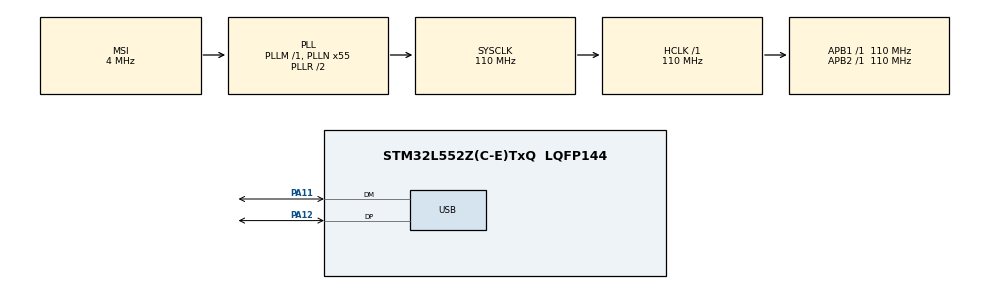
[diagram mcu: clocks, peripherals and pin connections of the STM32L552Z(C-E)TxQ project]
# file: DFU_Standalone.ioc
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Mcu.Family=STM32L5
Mcu.Name=STM32L552Z(C-E)TxQ
Mcu.Package=LQFP144
NVIC.PriorityGroup=NVIC_PRIORITYGROUP_3
NVIC.USB_FS_IRQn=true\:0\:0\:true\:false\:true\:false\:true\:true
PA11.GPIO_Speed=GPIO_SPEED_FREQ_VERY_HIGH
PA11.Mode=Device
PA11.Signal=USB_DM
PA12.GPIO_Speed=GPIO_SPEED_FREQ_VERY_HIGH
PA12.Mode=Device
PA12.Signal=USB_DP
ProjectManager.HeapSize=0x1000
ProjectManager.StackSize=0x1000
ProjectManager.TargetToolchain=EWARM V8.32
RCC.ADCCLockSelection=RCC_ADCCLKSOURCE_SYSCLK
RCC.ADCFreq_Value=110000000
RCC.AHBFreq_Value=110000000
RCC.APB1Freq_Value=110000000
RCC.APB1TimFreq_Value=110000000
RCC.APB2Freq_Value=110000000
RCC.APB2TimFreq_Value=110000000
RCC.CK48CLockSelection=RCC_USBCLKSOURCE_HSI48
RCC.CortexFreq_Value=110000000
RCC.DATA_CACHE_ENABLE=0
RCC.HCLKFreq_Value=110000000
RCC.HSE_VALUE=8000000
RCC.HSI48_VALUE=48000000
RCC.HSI_VALUE=16000000
RCC.INSTRUCTION_CACHE_ENABLE=0
RCC.LSE_VALUE=32768
RCC.MSI_VALUE=4000000
RCC.PLLN=55
RCC.SYSCLKFreq_VALUE=110000000
RCC.SYSCLKSource=RCC_SYSCLKSOURCE_PLLCLK
RCC.USBFreq_Value=48000000
RCC.VCOOutputFreq_Value=220000000
USB.DeviceSpeed=PCD_SPEED_FULL
USB.Sof_enable=DISABLE
USB.battery_charging_enable=DISABLE
USB.low_power_enable=DISABLE
USB.lpm_enable=DISABLE
USB.phy_itface=PCD_PHY_EMBEDDED
USB_DEVICE.CLASS_NAME_FS=DFU
USB_DEVICE.CONFIGURATION_STRING_DFU_FS=DFU Config
USB_DEVICE.INTERFACE_STRING_DFU_FS=DFU Interface
USB_DEVICE.LANGID_STRING=1033
USB_DEVICE.MANUFACTURER_STRING=STMicroelectronics
USB_DEVICE.PID_DFU_FS=0xdf11
USB_DEVICE.PRODUCT_STRING_DFU_FS=DFU in FS Mode
USB_DEVICE.USBD_DEBUG_LEVEL=0
USB_DEVICE.USBD_DFU_APP_DEFAULT_ADD=0x0800C000
USB_DEVICE.USBD_DFU_MAX_ITF_NUM=1
USB_DEVICE.USBD_DFU_MEDIA=@Internal Flash   /0x08000000/9*02Ka,247*02Kg
USB_DEVICE.USBD_DFU_XFER_SIZE=1024
USB_DEVICE.USBD_LPM_ENABLED=0
USB_DEVICE.USBD_MAX_NUM_CONFIGURATION=1
USB_DEVICE.USBD_MAX_NUM_INTERFACES=1
USB_DEVICE.USBD_MAX_STR_DESC_SIZ=48
USB_DEVICE.USBD_SELF_POWERED=1
USB_DEVICE.USBD_SUPPORT_USER_STRING_DESC=1
USB_DEVICE.VID=0x483
USB_DEVICE.VirtualMode=Dfu
USB_DEVICE.VirtualModeFS=Dfu_FS
VP_PWR_VS_DBSignals.Mode=DisableDeadBatterySignals
VP_PWR_VS_SECSignals.Mode=Security/Privilege
VP_RCC_USB.Mode=CRS SYNC Source USB
VP_USB_DEVICE_VS_USB_DEVICE_DFU_FS.Mode=DFU_FS
board=STM32L552E_EVAL

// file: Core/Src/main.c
/* USER CODE BEGIN Header */
/**
  ******************************************************************************
  * @file    USB_Device/DFU_Standalone/Core/Src/main.c
  * @author  MCD Application Team
  * @brief   USB device DFU demo main file
  ******************************************************************************
  * @attention
  *
  * Copyright (c) 2019 STMicroelectronics.
  * All rights reserved.
  *
  * This software is licensed under terms that can be found in the LICENSE file
  * in the root directory of this software component.
  * If no LICENSE file comes with this software, it is provided AS-IS.
  *
  ******************************************************************************
  */
/* USER CODE END Header */
#include "main.h"
#include "usb_device.h"

void SystemClock_Config(void);
static void MX_GPIO_Init(void);

int main(void)
{
  /* USER CODE BEGIN 1 */
  pFunction JumpToApplication;
  uint32_t JumpAddress;
  /* USER CODE END 1 */

  /* MCU Configuration--------------------------------------------------------*/

  /* Reset of all peripherals, Initializes the Flash interface and the Systick. */
  HAL_Init();

  /* Configure the system clock */
  SystemClock_Config();

  /* USER CODE BEGIN SysInit */

 /* Configure WKUP push-button */
  BSP_PB_Init(BUTTON_KEY, BUTTON_MODE_GPIO);

  /* Check if the WKUP push-button is pressed */
  if (BSP_PB_GetState(BUTTON_KEY) != GPIO_PIN_RESET)
  {
    /* Test if user code is programmed starting from address 0x0800C000 */
    if (((*(__IO uint32_t *) USBD_DFU_APP_DEFAULT_ADD) & 0x2FFC0000) ==
        0x20000000)
    {
      /* Jump to user application */
      JumpAddress = *(__IO uint32_t *) (USBD_DFU_APP_DEFAULT_ADD + 4);
      JumpToApplication = (pFunction) JumpAddress;

      /* Initialize user application's Stack Pointer */
      __set_MSP(*(__IO uint32_t *) USBD_DFU_APP_DEFAULT_ADD);
      JumpToApplication();
    }
  }

  /* USER CODE END SysInit */

  /* Initialize all configured peripherals */
  MX_GPIO_Init();
  MX_USB_Device_Init();

  /* Infinite loop */
  while (1)
  {

  }
}

void SystemClock_Config(void)
{
  RCC_OscInitTypeDef RCC_OscInitStruct = {0};
  RCC_ClkInitTypeDef RCC_ClkInitStruct = {0};
  RCC_CRSInitTypeDef RCC_CRSInitStruct = {0};

  /** Configure the main internal regulator output voltage
  */
  if (HAL_PWREx_ControlVoltageScaling(PWR_REGULATOR_VOLTAGE_SCALE0) != HAL_OK)
  {
    Error_Handler();
  }

  /** Initializes the RCC Oscillators according to the specified parameters
  * in the RCC_OscInitTypeDef structure.
  */
  RCC_OscInitStruct.OscillatorType = RCC_OSCILLATORTYPE_HSI48|RCC_OSCILLATORTYPE_MSI;
  RCC_OscInitStruct.HSI48State = RCC_HSI48_ON;
  RCC_OscInitStruct.MSIState = RCC_MSI_ON;
  RCC_OscInitStruct.MSICalibrationValue = RCC_MSICALIBRATION_DEFAULT;
  RCC_OscInitStruct.MSIClockRange = RCC_MSIRANGE_6;
  RCC_OscInitStruct.PLL.PLLState = RCC_PLL_ON;
  RCC_OscInitStruct.PLL.PLLSource = RCC_PLLSOURCE_MSI;
  RCC_OscInitStruct.PLL.PLLM = 1;
  RCC_OscInitStruct.PLL.PLLN = 55;
  RCC_OscInitStruct.PLL.PLLP = RCC_PLLP_DIV7;
  RCC_OscInitStruct.PLL.PLLQ = RCC_PLLQ_DIV2;
  RCC_OscInitStruct.PLL.PLLR = RCC_PLLR_DIV2;
  if (HAL_RCC_OscConfig(&RCC_OscInitStruct) != HAL_OK)
  {
    Error_Handler();
  }

  /** Initializes the CPU, AHB and APB buses clocks
  */
  RCC_ClkInitStruct.ClockType = RCC_CLOCKTYPE_HCLK|RCC_CLOCKTYPE_SYSCLK
                              |RCC_CLOCKTYPE_PCLK1|RCC_CLOCKTYPE_PCLK2;
  RCC_ClkInitStruct.SYSCLKSource = RCC_SYSCLKSOURCE_PLLCLK;
  RCC_ClkInitStruct.AHBCLKDivider = RCC_SYSCLK_DIV1;
  RCC_ClkInitStruct.APB1CLKDivider = RCC_HCLK_DIV1;
  RCC_ClkInitStruct.APB2CLKDivider = RCC_HCLK_DIV1;

  if (HAL_RCC_ClockConfig(&RCC_ClkInitStruct, FLASH_LATENCY_5) != HAL_OK)
  {
    Error_Handler();
  }

  /** Enable the SYSCFG APB clock
  */
  __HAL_RCC_CRS_CLK_ENABLE();

  /** Configures CRS
  */
  RCC_CRSInitStruct.Prescaler = RCC_CRS_SYNC_DIV1;
  RCC_CRSInitStruct.Source = RCC_CRS_SYNC_SOURCE_USB;
  RCC_CRSInitStruct.Polarity = RCC_CRS_SYNC_POLARITY_RISING;
  RCC_CRSInitStruct.ReloadValue = __HAL_RCC_CRS_RELOADVALUE_CALCULATE(48000000,1000);
  RCC_CRSInitStruct.ErrorLimitValue = 34;
  RCC_CRSInitStruct.HSI48CalibrationValue = 32;

  HAL_RCCEx_CRSConfig(&RCC_CRSInitStruct);
}

static void MX_GPIO_Init(void)
{

  /* GPIO Ports Clock Enable */
  __HAL_RCC_GPIOA_CLK_ENABLE();

}

/* USER CODE BEGIN 4 */
/**
  * @brief This function provides accurate delay (in milliseconds) based
  * on SysTick counter flag.
  * @note This function is declared as __weak to be overwritten in case of other
  * implementations in user file.
  * @param Delay: specifies the delay time length, in milliseconds.
  * @retval None
  */
void HAL_Delay(__IO uint32_t Delay)
{
  while (Delay)
  {
    if (SysTick->CTRL & SysTick_CTRL_COUNTFLAG_Msk)
    {
      Delay--;
    }
  }
}
/* USER CODE END 4 */

void Error_Handler(void)
{
  while (1)
  {
  }
}

#ifdef  USE_FULL_ASSERT
/**
  * @brief  Reports the name of the source file and the source line number
  *         where the assert_param error has occurred.
  * @param  file: pointer to the source file name
  * @param  line: assert_param error line source number
  * @retval None
  */
void assert_failed(uint8_t *file, uint32_t line)
{
  /* USER CODE BEGIN 6 */
  /* User can add his own implementation to report the file name and line number,
     ex: printf("Wrong parameters value: file %s on line %d\r\n", file, line) */
  /* Infinite loop */
  while (1)
  {}
  /* USER CODE END 6 */
}
#endif /* USE_FULL_ASSERT */
